# RP2350 register map
Vendor: Raspberry Pi; Series: RP; File version: 0.1
CPU: CM33 r1p0, little endian, MPU, FPU, DSP, VTOR, 4 interrupt priority bits, 52 interrupts, 8 SAU regions
Registers are 32-bit, read-write, reset 0x0 unless marked. A register's access mark holds for its fields unless they carry their own. Offsets are from the block's base; [hi:lo] are bit positions; lines under a group give offsets from that group; {n}, {i} and the like mark numbered series; 'fields as' and 'values as' point back to an identical list.

## IO_BANK0
Base 0x40028000
{0x0+8i} GPIO[{i}] (i=0..47) group
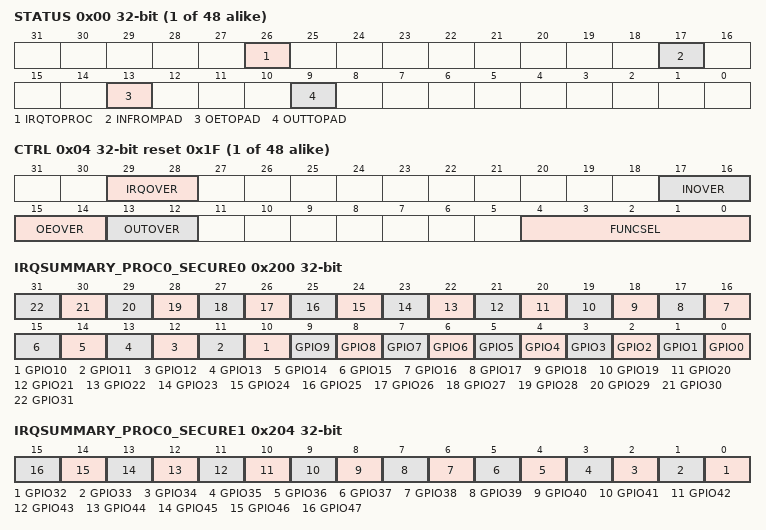
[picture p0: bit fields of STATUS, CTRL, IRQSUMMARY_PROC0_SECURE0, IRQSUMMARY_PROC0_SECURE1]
  0x00 STATUS — GPIO status
    [26] IRQTOPROC ro — interrupt to processors, after override is applied
    [17] INFROMPAD ro — input signal from pad, before override is applied
    [13] OETOPAD ro — output enable to pad after register override is applied
    [9] OUTTOPAD ro — output signal to pad after register override is applied
  0x04 CTRL reset 0x1F — GPIO control including function select and overrides.
    [29:28] IRQOVER
      0=NORMAL (don't invert the interrupt); 1=INVERT (invert the interrupt); 2=LOW (drive interrupt low); 3=HIGH (drive interrupt high)
    [17:16] INOVER
      0=NORMAL (don't invert the peri input); 1=INVERT (invert the peri input); 2=LOW (drive peri input low); 3=HIGH (drive peri input high)
    [15:14] OEOVER
      0=NORMAL (drive output enable from peripheral signal selected by funcsel); 1=INVERT (drive output enable from inverse of peripheral signal selected by funcsel); 2=DISABLE (disable output); 3=ENABLE (enable output)
    [13:12] OUTOVER
      0=NORMAL (drive output from peripheral signal selected by funcsel); 1=INVERT (drive output from inverse of peripheral signal selected by funcsel); 2=LOW (drive output low); 3=HIGH (drive output high)
    [4:0] FUNCSEL — 0-31 -> selects pin function according to the gpio table. 31 == NULL
      0=jtag_hstx (JTAG on GPIO0-3, HSTX on GPIO12-19; unavailable on other pins); 1=spi (SPI0/SPI1); 2=UART0/UART1; 3=i2c (I2C0/I2C1); 4=pwm (PWM slice A/B input or output); 5=sio (Software control of the pin via SIO); 6=pio0; 7=pio1; 8=pio2; 9=misc (XIP CS1, CoreSight trace or clock GPIN/GPOUT depending on pin; unavailable on most pins); 10=usb (USB power-control muxing (VBUS detect/enable, overcurrent detect)); 11=uart_aux (Second UART mapping, on even/odd pin pairs GPIO2/3 through GPIO46/47); 31=null (No function selected; pin is driven by neither peripheral nor SIO)
0x200 IRQSUMMARY_PROC0_SECURE0
  [n] GPIO{n} ro (n=0..31)
0x204 IRQSUMMARY_PROC0_SECURE1
  [n-32] GPIO{n} ro (n=32..47)
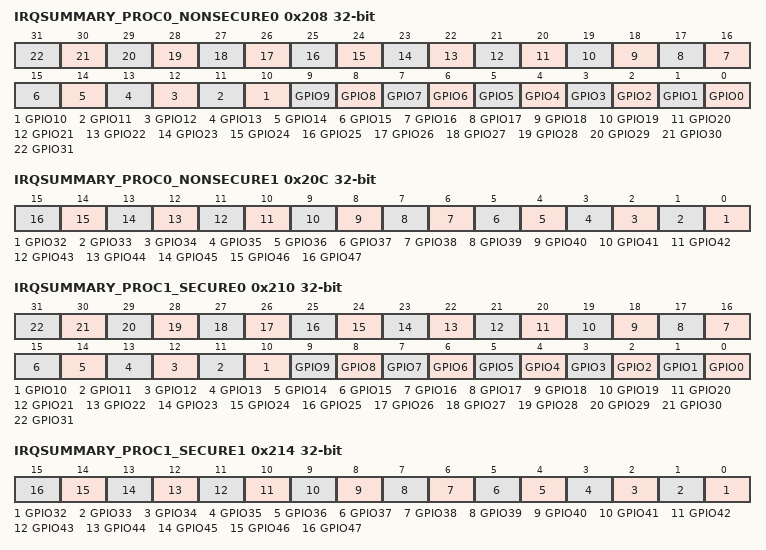
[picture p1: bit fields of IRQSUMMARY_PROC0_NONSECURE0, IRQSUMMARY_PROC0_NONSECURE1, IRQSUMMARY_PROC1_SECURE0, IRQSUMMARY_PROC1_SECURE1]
0x208 IRQSUMMARY_PROC0_NONSECURE0
  [n] GPIO{n} ro (n=0..31)
0x20C IRQSUMMARY_PROC0_NONSECURE1
  [n-32] GPIO{n} ro (n=32..47)
0x210 IRQSUMMARY_PROC1_SECURE0
  [n] GPIO{n} ro (n=0..31)
0x214 IRQSUMMARY_PROC1_SECURE1
  [n-32] GPIO{n} ro (n=32..47)
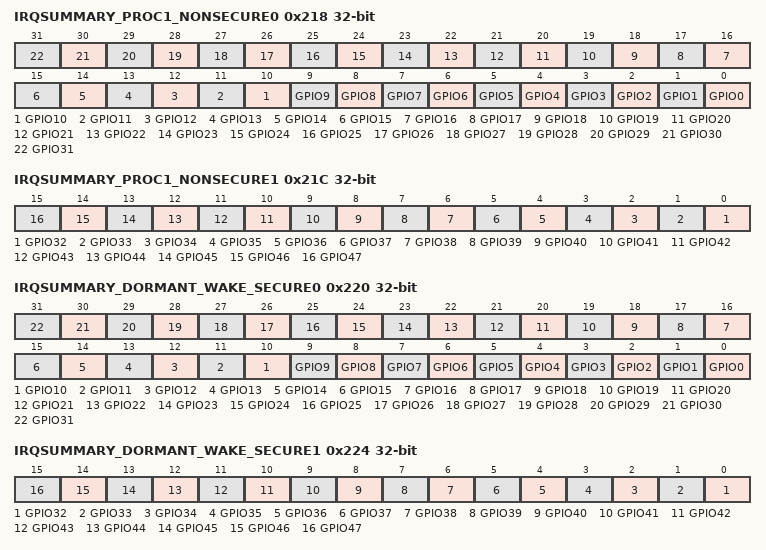
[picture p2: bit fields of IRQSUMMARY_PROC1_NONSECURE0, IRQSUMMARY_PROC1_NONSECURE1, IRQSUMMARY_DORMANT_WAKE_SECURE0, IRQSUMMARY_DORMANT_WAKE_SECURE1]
0x218 IRQSUMMARY_PROC1_NONSECURE0
  [n] GPIO{n} ro (n=0..31)
0x21C IRQSUMMARY_PROC1_NONSECURE1
  [n-32] GPIO{n} ro (n=32..47)
0x220 IRQSUMMARY_DORMANT_WAKE_SECURE0
  [n] GPIO{n} ro (n=0..31)
0x224 IRQSUMMARY_DORMANT_WAKE_SECURE1
  [n-32] GPIO{n} ro (n=32..47)
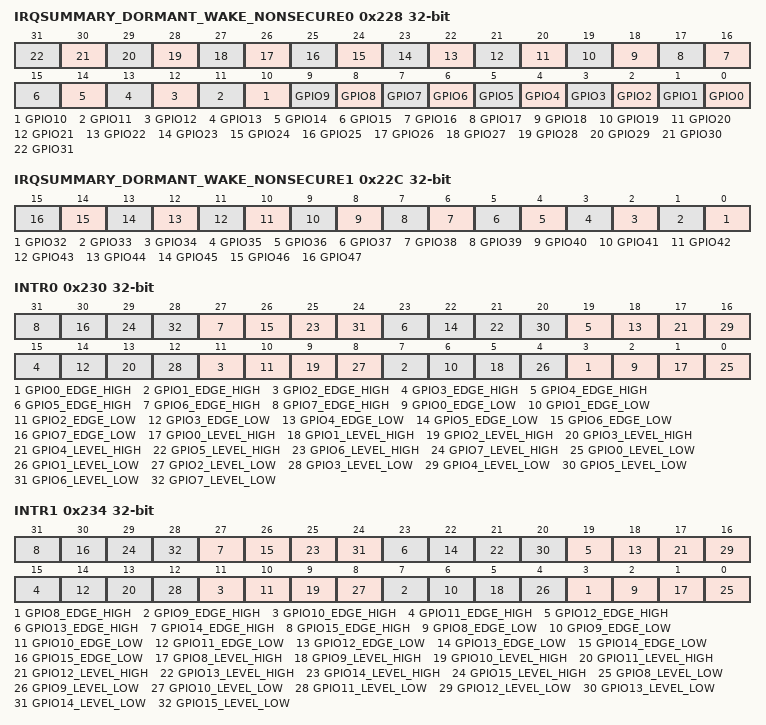
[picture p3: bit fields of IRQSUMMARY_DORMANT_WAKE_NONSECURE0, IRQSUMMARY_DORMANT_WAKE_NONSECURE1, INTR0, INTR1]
0x228 IRQSUMMARY_DORMANT_WAKE_NONSECURE0
  [n] GPIO{n} ro (n=0..31)
0x22C IRQSUMMARY_DORMANT_WAKE_NONSECURE1
  [n-32] GPIO{n} ro (n=32..47)
0x230 INTR0 — Raw Interrupts
  [4n+3] GPIO{n}_EDGE_HIGH write-1-clears (n=0..7), [4n+2] GPIO{n}_EDGE_LOW write-1-clears (n=0..7), [4n+1] GPIO{n}_LEVEL_HIGH ro (n=0..7), [4n] GPIO{n}_LEVEL_LOW ro (n=0..7)
0x234 INTR1 — Raw Interrupts
  [4n-29] GPIO{n}_EDGE_HIGH write-1-clears (n=8..15), [4n-30] GPIO{n}_EDGE_LOW write-1-clears (n=8..15), [4n-31] GPIO{n}_LEVEL_HIGH ro (n=8..15), [4n-32] GPIO{n}_LEVEL_LOW ro (n=8..15)
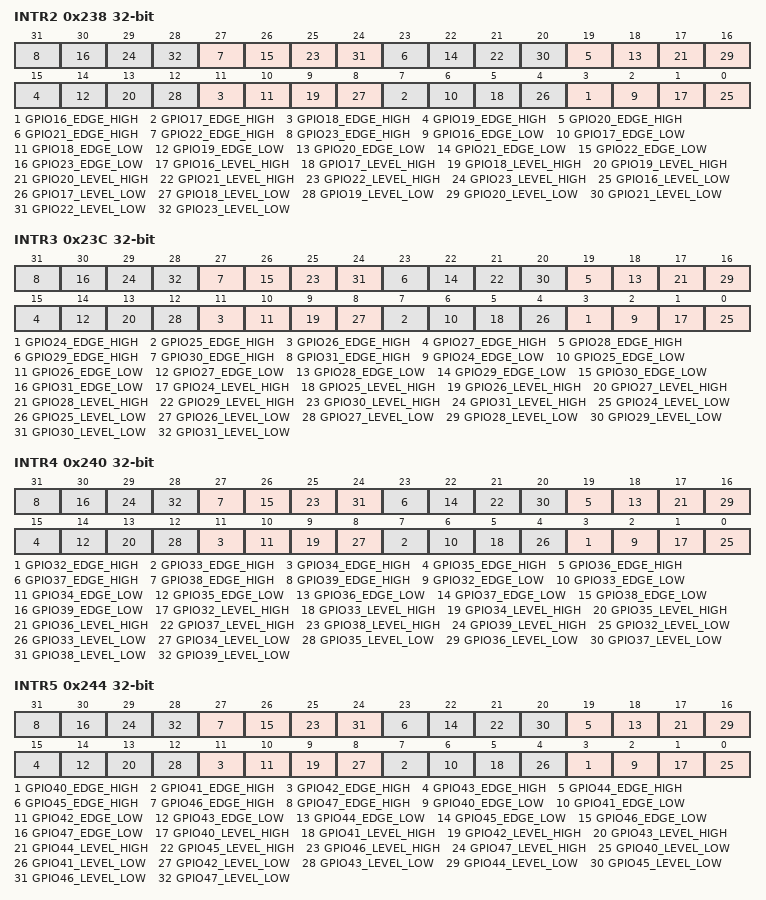
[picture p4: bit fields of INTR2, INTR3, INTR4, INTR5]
0x238 INTR2 — Raw Interrupts
  [4n-61] GPIO{n}_EDGE_HIGH write-1-clears (n=16..23), [4n-62] GPIO{n}_EDGE_LOW write-1-clears (n=16..23), [4n-63] GPIO{n}_LEVEL_HIGH ro (n=16..23), [4n-64] GPIO{n}_LEVEL_LOW ro (n=16..23)
0x23C INTR3 — Raw Interrupts
  [4n-93] GPIO{n}_EDGE_HIGH write-1-clears (n=24..31), [4n-94] GPIO{n}_EDGE_LOW write-1-clears (n=24..31), [4n-95] GPIO{n}_LEVEL_HIGH ro (n=24..31), [4n-96] GPIO{n}_LEVEL_LOW ro (n=24..31)
0x240 INTR4 — Raw Interrupts
  [4n-125] GPIO{n}_EDGE_HIGH write-1-clears (n=32..39), [4n-126] GPIO{n}_EDGE_LOW write-1-clears (n=32..39), [4n-127] GPIO{n}_LEVEL_HIGH ro (n=32..39), [4n-128] GPIO{n}_LEVEL_LOW ro (n=32..39)
0x244 INTR5 — Raw Interrupts
  [4n-157] GPIO{n}_EDGE_HIGH write-1-clears (n=40..47), [4n-158] GPIO{n}_EDGE_LOW write-1-clears (n=40..47), [4n-159] GPIO{n}_LEVEL_HIGH ro (n=40..47), [4n-160] GPIO{n}_LEVEL_LOW ro (n=40..47)
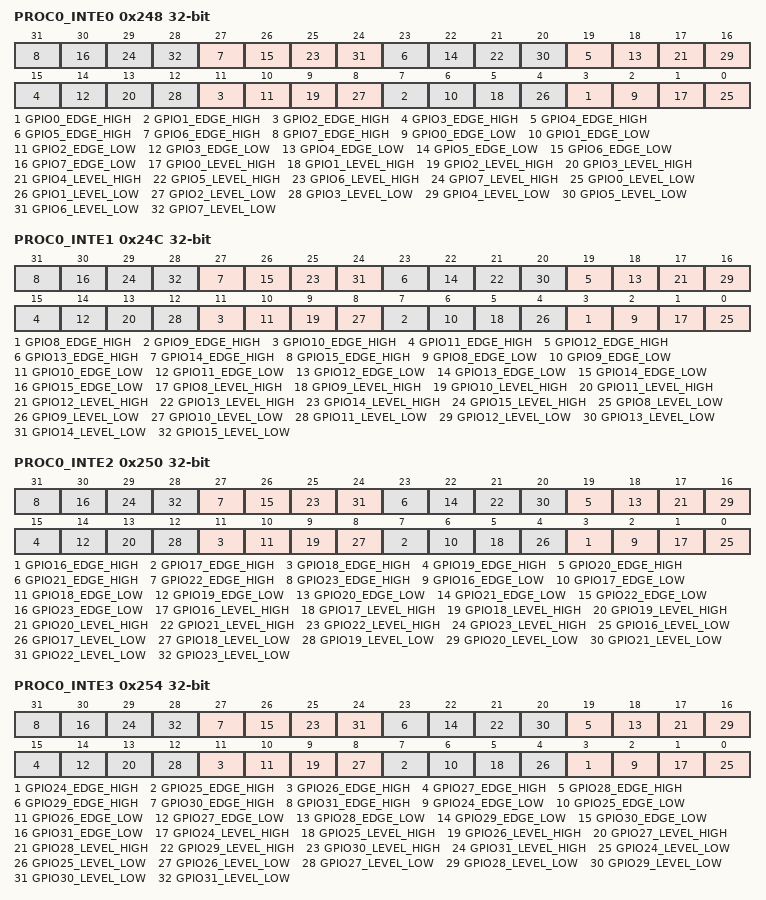
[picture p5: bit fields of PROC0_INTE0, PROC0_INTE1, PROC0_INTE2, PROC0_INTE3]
0x248 PROC0_INTE0 — Interrupt Enable for proc0
  [4n+3] GPIO{n}_EDGE_HIGH (n=0..7), [4n+2] GPIO{n}_EDGE_LOW (n=0..7), [4n+1] GPIO{n}_LEVEL_HIGH (n=0..7), [4n] GPIO{n}_LEVEL_LOW (n=0..7)
0x24C PROC0_INTE1 — Interrupt Enable for proc0
  [4n-29] GPIO{n}_EDGE_HIGH (n=8..15), [4n-30] GPIO{n}_EDGE_LOW (n=8..15), [4n-31] GPIO{n}_LEVEL_HIGH (n=8..15), [4n-32] GPIO{n}_LEVEL_LOW (n=8..15)
0x250 PROC0_INTE2 — Interrupt Enable for proc0
  [4n-61] GPIO{n}_EDGE_HIGH (n=16..23), [4n-62] GPIO{n}_EDGE_LOW (n=16..23), [4n-63] GPIO{n}_LEVEL_HIGH (n=16..23), [4n-64] GPIO{n}_LEVEL_LOW (n=16..23)
0x254 PROC0_INTE3 — Interrupt Enable for proc0
  [4n-93] GPIO{n}_EDGE_HIGH (n=24..31), [4n-94] GPIO{n}_EDGE_LOW (n=24..31), [4n-95] GPIO{n}_LEVEL_HIGH (n=24..31), [4n-96] GPIO{n}_LEVEL_LOW (n=24..31)
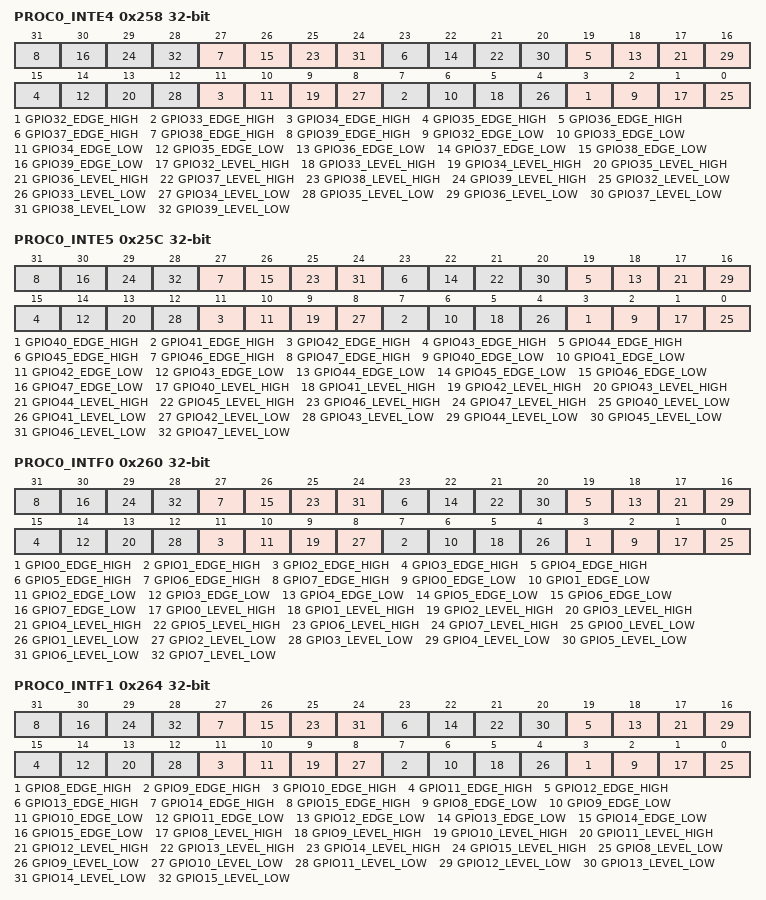
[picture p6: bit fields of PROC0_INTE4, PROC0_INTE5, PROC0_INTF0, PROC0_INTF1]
0x258 PROC0_INTE4 — Interrupt Enable for proc0
  [4n-125] GPIO{n}_EDGE_HIGH (n=32..39), [4n-126] GPIO{n}_EDGE_LOW (n=32..39), [4n-127] GPIO{n}_LEVEL_HIGH (n=32..39), [4n-128] GPIO{n}_LEVEL_LOW (n=32..39)
0x25C PROC0_INTE5 — Interrupt Enable for proc0
  [4n-157] GPIO{n}_EDGE_HIGH (n=40..47), [4n-158] GPIO{n}_EDGE_LOW (n=40..47), [4n-159] GPIO{n}_LEVEL_HIGH (n=40..47), [4n-160] GPIO{n}_LEVEL_LOW (n=40..47)
0x260 PROC0_INTF0 — Interrupt Force for proc0
  fields as PROC0_INTE0
0x264 PROC0_INTF1 — Interrupt Force for proc0
  fields as PROC0_INTE1
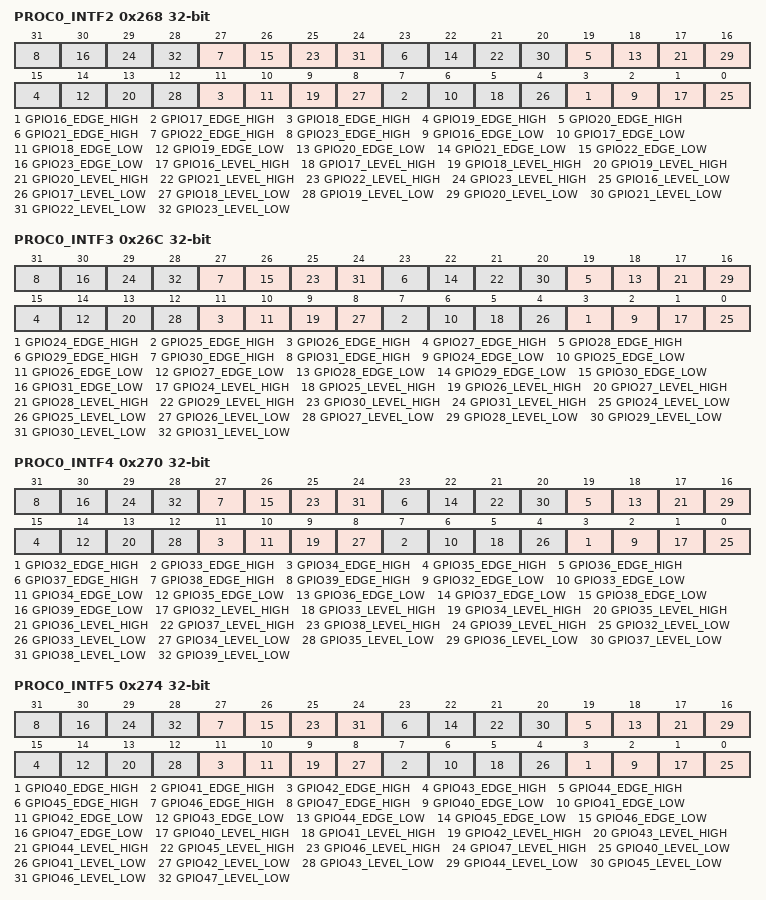
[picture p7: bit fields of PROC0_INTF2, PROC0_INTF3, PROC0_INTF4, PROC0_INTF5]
0x268 PROC0_INTF2 — Interrupt Force for proc0
  fields as PROC0_INTE2
0x26C PROC0_INTF3 — Interrupt Force for proc0
  fields as PROC0_INTE3
0x270 PROC0_INTF4 — Interrupt Force for proc0
  fields as PROC0_INTE4
0x274 PROC0_INTF5 — Interrupt Force for proc0
  fields as PROC0_INTE5
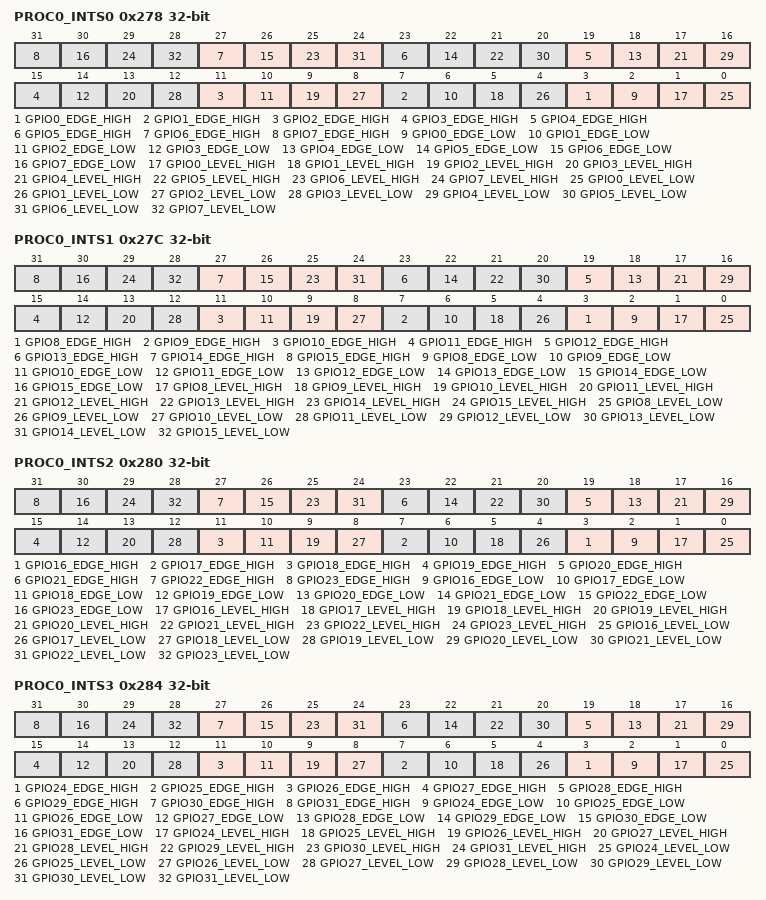
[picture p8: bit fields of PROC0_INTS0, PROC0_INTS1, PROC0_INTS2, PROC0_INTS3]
0x278 PROC0_INTS0 — Interrupt status after masking & forcing for proc0
  [4n+3] GPIO{n}_EDGE_HIGH ro (n=0..7), [4n+2] GPIO{n}_EDGE_LOW ro (n=0..7), [4n+1] GPIO{n}_LEVEL_HIGH ro (n=0..7), [4n] GPIO{n}_LEVEL_LOW ro (n=0..7)
0x27C PROC0_INTS1 — Interrupt status after masking & forcing for proc0
  [4n-29] GPIO{n}_EDGE_HIGH ro (n=8..15), [4n-30] GPIO{n}_EDGE_LOW ro (n=8..15), [4n-31] GPIO{n}_LEVEL_HIGH ro (n=8..15), [4n-32] GPIO{n}_LEVEL_LOW ro (n=8..15)
0x280 PROC0_INTS2 — Interrupt status after masking & forcing for proc0
  [4n-61] GPIO{n}_EDGE_HIGH ro (n=16..23), [4n-62] GPIO{n}_EDGE_LOW ro (n=16..23), [4n-63] GPIO{n}_LEVEL_HIGH ro (n=16..23), [4n-64] GPIO{n}_LEVEL_LOW ro (n=16..23)
0x284 PROC0_INTS3 — Interrupt status after masking & forcing for proc0
  [4n-93] GPIO{n}_EDGE_HIGH ro (n=24..31), [4n-94] GPIO{n}_EDGE_LOW ro (n=24..31), [4n-95] GPIO{n}_LEVEL_HIGH ro (n=24..31), [4n-96] GPIO{n}_LEVEL_LOW ro (n=24..31)
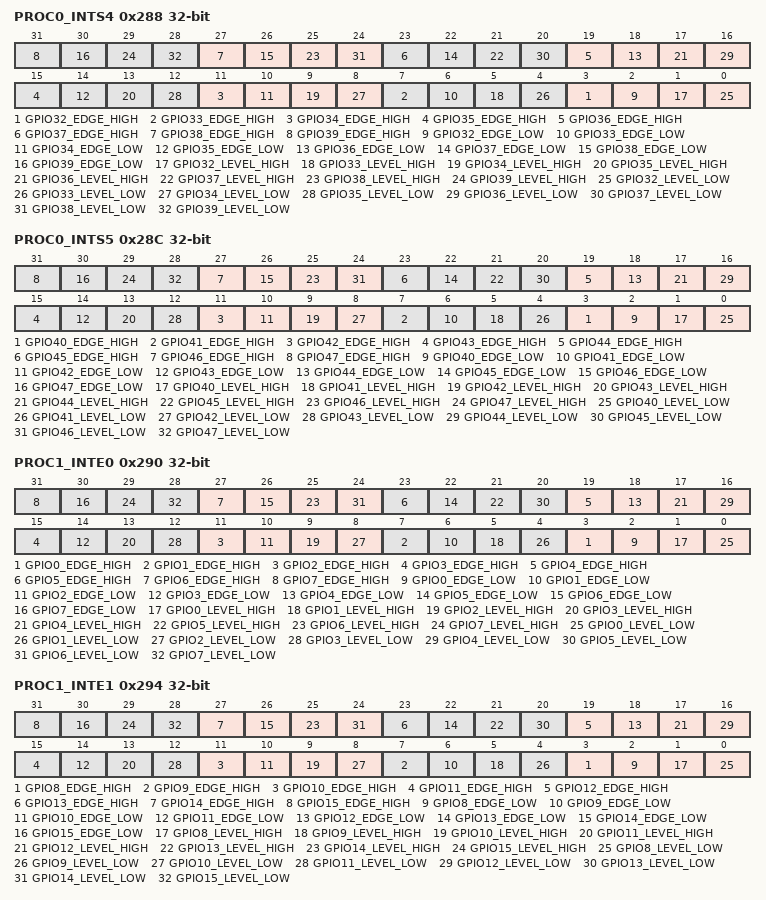
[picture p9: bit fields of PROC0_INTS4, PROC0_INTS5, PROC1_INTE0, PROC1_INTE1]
0x288 PROC0_INTS4 — Interrupt status after masking & forcing for proc0
  [4n-125] GPIO{n}_EDGE_HIGH ro (n=32..39), [4n-126] GPIO{n}_EDGE_LOW ro (n=32..39), [4n-127] GPIO{n}_LEVEL_HIGH ro (n=32..39), [4n-128] GPIO{n}_LEVEL_LOW ro (n=32..39)
0x28C PROC0_INTS5 — Interrupt status after masking & forcing for proc0
  [4n-157] GPIO{n}_EDGE_HIGH ro (n=40..47), [4n-158] GPIO{n}_EDGE_LOW ro (n=40..47), [4n-159] GPIO{n}_LEVEL_HIGH ro (n=40..47), [4n-160] GPIO{n}_LEVEL_LOW ro (n=40..47)
0x290 PROC1_INTE0 — Interrupt Enable for proc1
  fields as PROC0_INTE0
0x294 PROC1_INTE1 — Interrupt Enable for proc1
  fields as PROC0_INTE1
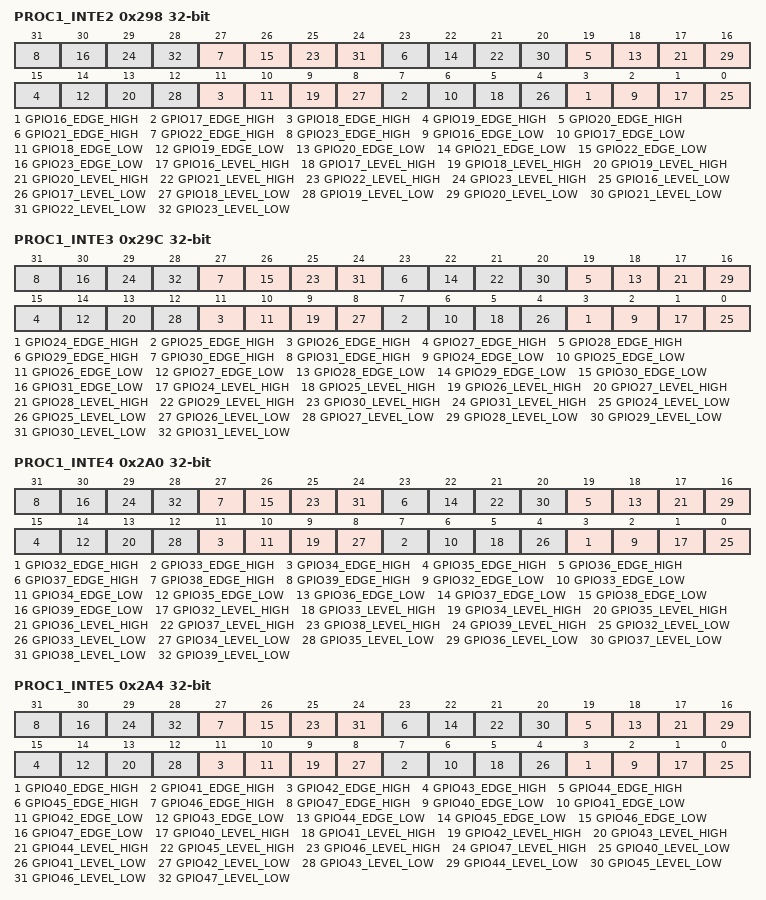
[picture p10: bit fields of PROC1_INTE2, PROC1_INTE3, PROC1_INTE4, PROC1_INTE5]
0x298 PROC1_INTE2 — Interrupt Enable for proc1
  fields as PROC0_INTE2
0x29C PROC1_INTE3 — Interrupt Enable for proc1
  fields as PROC0_INTE3
0x2A0 PROC1_INTE4 — Interrupt Enable for proc1
  fields as PROC0_INTE4
0x2A4 PROC1_INTE5 — Interrupt Enable for proc1
  fields as PROC0_INTE5
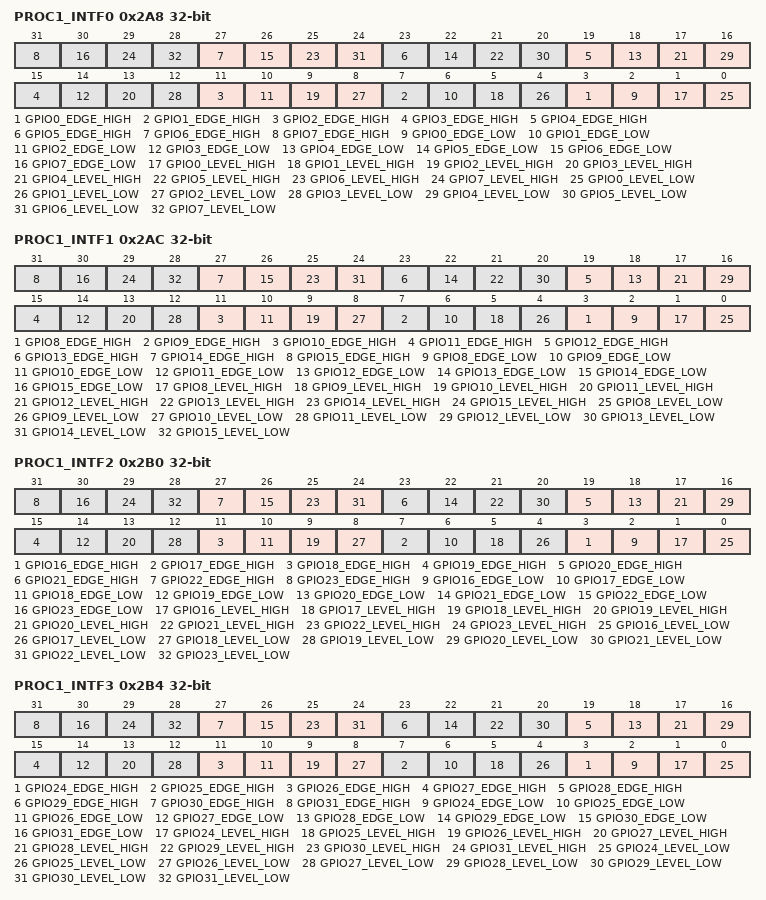
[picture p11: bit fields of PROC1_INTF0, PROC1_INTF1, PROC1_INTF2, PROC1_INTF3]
0x2A8 PROC1_INTF0 — Interrupt Force for proc1
  fields as PROC0_INTE0
0x2AC PROC1_INTF1 — Interrupt Force for proc1
  fields as PROC0_INTE1
0x2B0 PROC1_INTF2 — Interrupt Force for proc1
  fields as PROC0_INTE2
0x2B4 PROC1_INTF3 — Interrupt Force for proc1
  fields as PROC0_INTE3
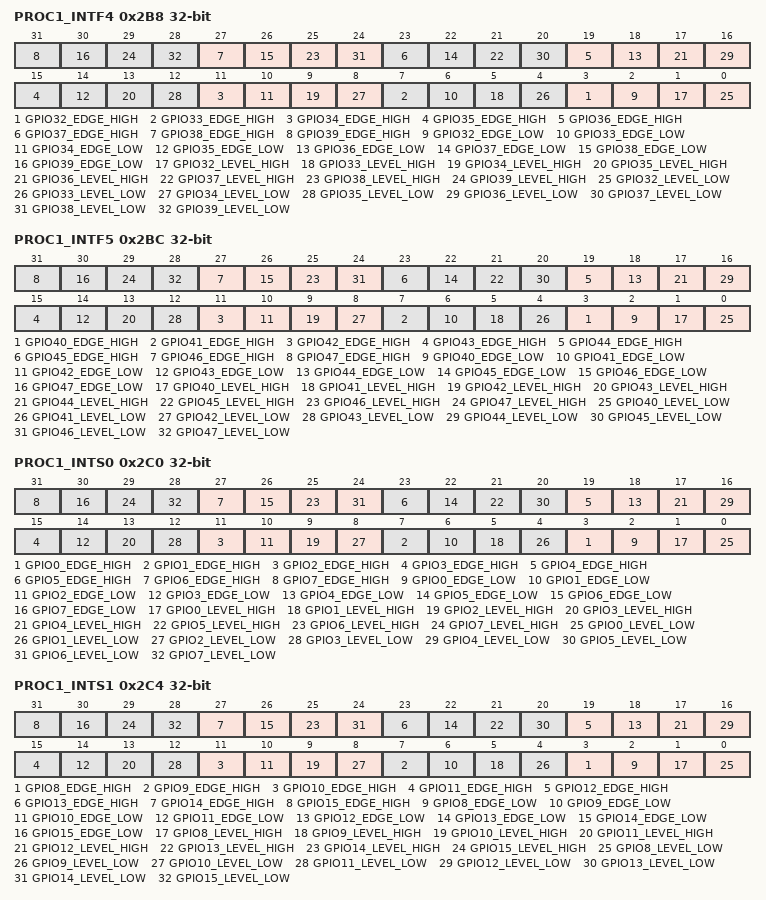
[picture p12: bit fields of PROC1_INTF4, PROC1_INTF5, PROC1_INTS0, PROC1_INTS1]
0x2B8 PROC1_INTF4 — Interrupt Force for proc1
  fields as PROC0_INTE4
0x2BC PROC1_INTF5 — Interrupt Force for proc1
  fields as PROC0_INTE5
0x2C0 PROC1_INTS0 — Interrupt status after masking & forcing for proc1
  fields as PROC0_INTS0
0x2C4 PROC1_INTS1 — Interrupt status after masking & forcing for proc1
  fields as PROC0_INTS1
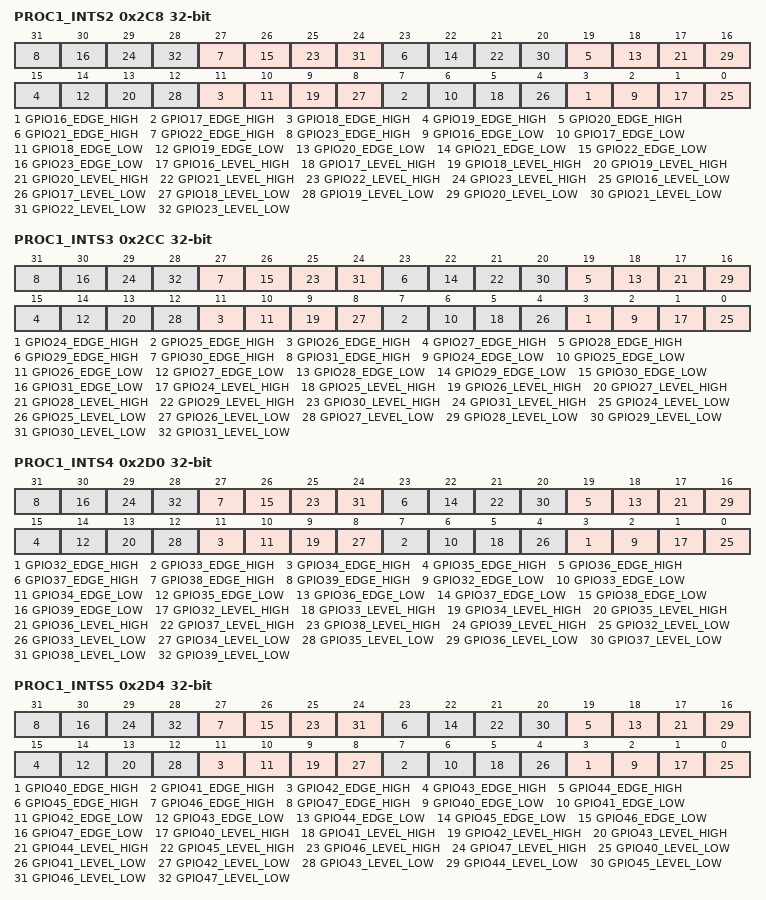
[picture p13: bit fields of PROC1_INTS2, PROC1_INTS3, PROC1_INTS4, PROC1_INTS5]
0x2C8 PROC1_INTS2 — Interrupt status after masking & forcing for proc1
  fields as PROC0_INTS2
0x2CC PROC1_INTS3 — Interrupt status after masking & forcing for proc1
  fields as PROC0_INTS3
0x2D0 PROC1_INTS4 — Interrupt status after masking & forcing for proc1
  fields as PROC0_INTS4
0x2D4 PROC1_INTS5 — Interrupt status after masking & forcing for proc1
  fields as PROC0_INTS5
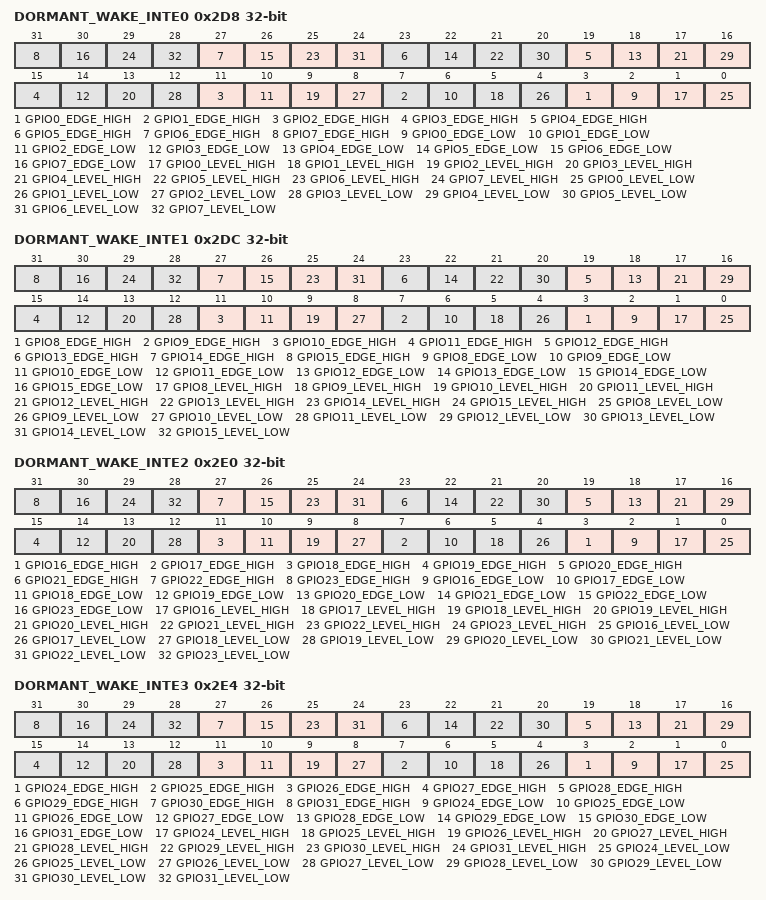
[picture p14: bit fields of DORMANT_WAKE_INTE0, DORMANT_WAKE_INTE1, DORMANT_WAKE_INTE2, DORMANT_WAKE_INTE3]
0x2D8 DORMANT_WAKE_INTE0 — Interrupt Enable for dormant_wake
  fields as PROC0_INTE0
0x2DC DORMANT_WAKE_INTE1 — Interrupt Enable for dormant_wake
  fields as PROC0_INTE1
0x2E0 DORMANT_WAKE_INTE2 — Interrupt Enable for dormant_wake
  fields as PROC0_INTE2
0x2E4 DORMANT_WAKE_INTE3 — Interrupt Enable for dormant_wake
  fields as PROC0_INTE3
0x2E8 DORMANT_WAKE_INTE4 — Interrupt Enable for dormant_wake
  fields as PROC0_INTE4
0x2EC DORMANT_WAKE_INTE5 — Interrupt Enable for dormant_wake
  fields as PROC0_INTE5
0x2F0 DORMANT_WAKE_INTF0 — Interrupt Force for dormant_wake
  fields as PROC0_INTE0
0x2F4 DORMANT_WAKE_INTF1 — Interrupt Force for dormant_wake
  fields as PROC0_INTE1
0x2F8 DORMANT_WAKE_INTF2 — Interrupt Force for dormant_wake
  fields as PROC0_INTE2
0x2FC DORMANT_WAKE_INTF3 — Interrupt Force for dormant_wake
  fields as PROC0_INTE3
0x300 DORMANT_WAKE_INTF4 — Interrupt Force for dormant_wake
  fields as PROC0_INTE4
0x304 DORMANT_WAKE_INTF5 — Interrupt Force for dormant_wake
  fields as PROC0_INTE5
0x308 DORMANT_WAKE_INTS0 — Interrupt status after masking & forcing for dormant_wake
  fields as PROC0_INTS0
0x30C DORMANT_WAKE_INTS1 — Interrupt status after masking & forcing for dormant_wake
  fields as PROC0_INTS1
0x310 DORMANT_WAKE_INTS2 — Interrupt status after masking & forcing for dormant_wake
  fields as PROC0_INTS2
0x314 DORMANT_WAKE_INTS3 — Interrupt status after masking & forcing for dormant_wake
  fields as PROC0_INTS3
0x318 DORMANT_WAKE_INTS4 — Interrupt status after masking & forcing for dormant_wake
  fields as PROC0_INTS4
0x31C DORMANT_WAKE_INTS5 — Interrupt status after masking & forcing for dormant_wake
  fields as PROC0_INTS5
